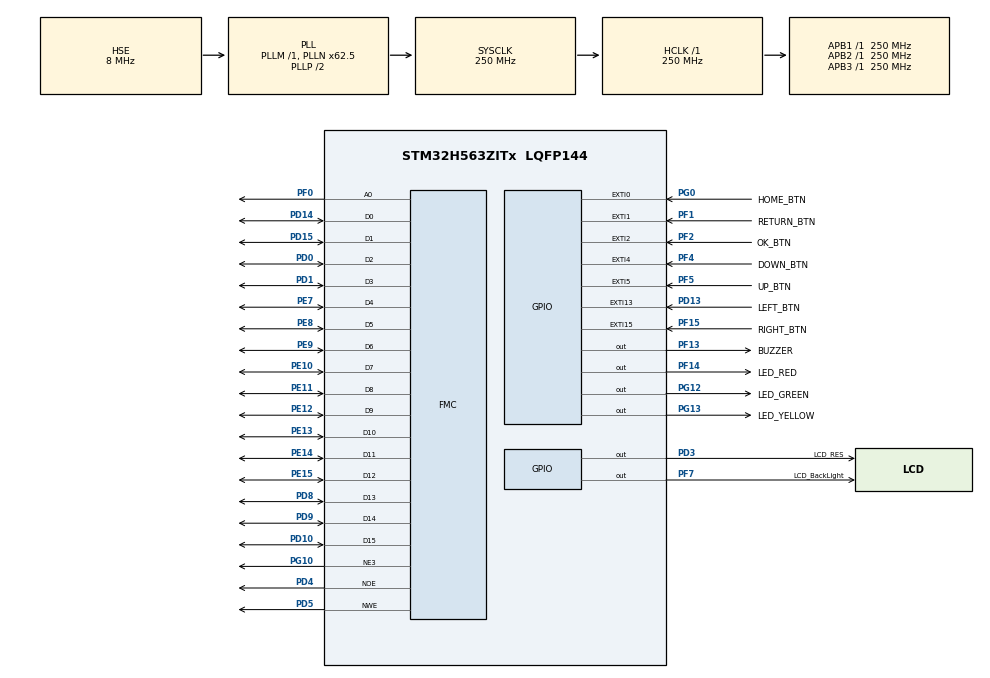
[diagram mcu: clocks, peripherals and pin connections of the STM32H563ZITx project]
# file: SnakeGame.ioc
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BOOTPATH.BootPathName=LEGACY
BOOTPATH.UserSelectedBootPath=LEGACY
CORTEX_M33_NS.Number-Cortex_Memory_Protection_Unit_Region0_OTP_RO_AREAS_Settings=MPU_REGION_NUMBER0
CORTEX_M33_NS.default_mode_Activation=1
CORTEX_M33_NS.userName=CORTEX_M33
FMC.AddressSetupTime1=3
FMC.BusTurnAroundDuration1=0
FMC.DataHoldTime1=3
FMC.DataSetupTime1=4
FMC.ExtendedMode1=FMC_EXTENDED_MODE_DISABLE
Mcu.Family=STM32H5
Mcu.Name=STM32H563ZITx
Mcu.Package=LQFP144
NVIC.EXTI0_IRQn=true\:0\:0\:false\:false\:true\:true\:true\:true
NVIC.EXTI13_IRQn=true\:0\:0\:false\:false\:true\:true\:true\:true
NVIC.EXTI15_IRQn=true\:0\:0\:false\:false\:true\:true\:true\:true
NVIC.EXTI1_IRQn=true\:0\:0\:false\:false\:true\:true\:true\:true
NVIC.EXTI2_IRQn=true\:0\:0\:false\:false\:true\:true\:true\:true
NVIC.EXTI4_IRQn=true\:0\:0\:false\:false\:true\:true\:true\:true
NVIC.EXTI5_IRQn=true\:0\:0\:false\:false\:true\:true\:true\:true
NVIC.PriorityGroup=NVIC_PRIORITYGROUP_4
NVIC.TIM6_IRQn=true\:0\:0\:false\:false\:true\:true\:true\:true
NVIC.TIM7_IRQn=true\:0\:0\:false\:false\:true\:true\:true\:true
PA13(JTMS/SWDIO).Mode=Serial_Wire
PA13(JTMS/SWDIO).Signal=DEBUG_JTMS-SWDIO
PA14(JTCK/SWCLK).Mode=Serial_Wire
PA14(JTCK/SWCLK).Signal=DEBUG_JTCK-SWCLK
PD0.Signal=FMC_D2_DA2
PD1.Signal=FMC_D3_DA3
PD10.Signal=FMC_D15_DA15
PD13.GPIO_Label=LEFT_BTN
PD13.GPIO_ModeDefaultEXTI=GPIO_MODE_IT_FALLING
PD13.GPIO_PuPd=GPIO_PULLUP
PD13.Signal=GPXTI13
PD14.Signal=FMC_D0_DA0
PD15.Signal=FMC_D1_DA1
PD3.GPIO_Label=LCD_RES
PD3.Signal=GPIO_Output
PD4.Signal=FMC_NOE
PD5.Signal=FMC_NWE
PD8.Signal=FMC_D13_DA13
PD9.Signal=FMC_D14_DA14
PE10.Signal=FMC_D7_DA7
PE11.Signal=FMC_D8_DA8
PE12.Signal=FMC_D9_DA9
PE13.Signal=FMC_D10_DA10
PE14.Signal=FMC_D11_DA11
PE15.Signal=FMC_D12_DA12
PE7.Signal=FMC_D4_DA4
PE8.Signal=FMC_D5_DA5
PE9.Signal=FMC_D6_DA6
PF0.Signal=FMC_A0
PF1.GPIO_Label=RETURN_BTN
PF1.GPIO_ModeDefaultEXTI=GPIO_MODE_IT_FALLING
PF1.GPIO_PuPd=GPIO_PULLUP
PF1.Signal=GPXTI1
PF13.GPIO_Label=BUZZER
PF13.GPIO_PuPd=GPIO_NOPULL
PF13.Signal=GPIO_Output
PF14.GPIO_Label=LED_RED
PF14.Signal=GPIO_Output
PF15.GPIO_Label=RIGHT_BTN
PF15.GPIO_ModeDefaultEXTI=GPIO_MODE_IT_FALLING
PF15.GPIO_PuPd=GPIO_PULLUP
PF15.Signal=GPXTI15
PF2.GPIO_Label=OK_BTN
PF2.GPIO_ModeDefaultEXTI=GPIO_MODE_IT_FALLING
PF2.GPIO_PuPd=GPIO_PULLUP
PF2.Signal=GPXTI2
PF4.GPIO_Label=DOWN_BTN
PF4.Signal=GPXTI4
PF5.GPIO_Label=UP_BTN
PF5.GPIO_ModeDefaultEXTI=GPIO_MODE_IT_FALLING
PF5.GPIO_PuPd=GPIO_PULLUP
PF5.Signal=GPXTI5
PF7.GPIO_Label=LCD_BackLight
PF7.Signal=GPIO_Output
PG0.GPIO_Label=HOME_BTN
PG0.GPIO_ModeDefaultEXTI=GPIO_MODE_IT_FALLING
PG0.GPIO_PuPd=GPIO_PULLUP
PG0.Signal=GPXTI0
PG10.Mode=NorPsramChipSelect3_1
PG10.Signal=FMC_NE3
PG12.GPIO_Label=LED_GREEN
PG12.Signal=GPIO_Output
PG13.GPIO_Label=LED_YELLOW
PG13.Signal=GPIO_Output
PH0-OSC_IN(PH0).Mode=HSE-External-Oscillator
PH0-OSC_IN(PH0).Signal=RCC_OSC_IN
PH1-OSC_OUT(PH1).Mode=HSE-External-Oscillator
PH1-OSC_OUT(PH1).Signal=RCC_OSC_OUT
ProjectManager.HeapSize=0x200
ProjectManager.StackSize=0x400
ProjectManager.TargetToolchain=EWARM V9.20
RCC.ADCFreq_Value=250000000
RCC.AHBFreq_Value=250000000
RCC.APB1Freq_Value=250000000
RCC.APB1TimFreq_Value=250000000
RCC.APB2Freq_Value=250000000
RCC.APB2TimFreq_Value=250000000
RCC.APB3Freq_Value=250000000
RCC.CSI_VALUE=4000000
RCC.CortexFreq_Value=250000000
RCC.EPOD_VALUE=8000000
RCC.HCLKFreq_Value=250000000
RCC.HSE_VALUE=8000000
RCC.HSI48_VALUE=48000000
RCC.HSI_VALUE=64000000
RCC.LSE_VALUE=32768
RCC.LSIRC_VALUE=32000
RCC.PLL2FRACN=0
RCC.PLL3FRACN=0
RCC.PLLFRACN=4096
RCC.PLLN=62
RCC.PLLSourceVirtual=RCC_PLL1_SOURCE_HSE
RCC.SYSCLKFreq_VALUE=250000000
RCC.SYSCLKSource=RCC_SYSCLKSOURCE_PLLCLK
RCC.USBFreq_Value=48000000
RCC.VCOOutputFreq_Value=500000000
SH.FMC_A0.0=FMC_A0,A0_1
SH.FMC_D0_DA0.0=FMC_D0,16b-d1
SH.FMC_D10_DA10.0=FMC_D10,16b-d1
SH.FMC_D11_DA11.0=FMC_D11,16b-d1
SH.FMC_D12_DA12.0=FMC_D12,16b-d1
SH.FMC_D13_DA13.0=FMC_D13,16b-d1
SH.FMC_D14_DA14.0=FMC_D14,16b-d1
SH.FMC_D15_DA15.0=FMC_D15,16b-d1
SH.FMC_D1_DA1.0=FMC_D1,16b-d1
SH.FMC_D2_DA2.0=FMC_D2,16b-d1
SH.FMC_D3_DA3.0=FMC_D3,16b-d1
SH.FMC_D4_DA4.0=FMC_D4,16b-d1
SH.FMC_D5_DA5.0=FMC_D5,16b-d1
SH.FMC_D6_DA6.0=FMC_D6,16b-d1
SH.FMC_D7_DA7.0=FMC_D7,16b-d1
SH.FMC_D8_DA8.0=FMC_D8,16b-d1
SH.FMC_D9_DA9.0=FMC_D9,16b-d1
SH.FMC_NOE.0=FMC_NOE,Lcd1
SH.FMC_NWE.0=FMC_NWE,Lcd1
TIM6.PeriodNoDither=99
TIM6.Prescaler=249
TIM7.PeriodNoDither=99
TIM7.Prescaler=249
VP_BOOTPATH_VS_BOOTPATH.Mode=BP_Activate
VP_CORTEX_M33_NS_VS_Hclk.Mode=Hclk_Mode
VP_ICACHE_VS_ICACHE.Mode=DirectMappedCache
VP_MEMORYMAP_VS_MEMORYMAP.Mode=CurAppReg
VP_PWR_VS_LPOM.Mode=PowerOptimisation
VP_PWR_VS_SECSignals.Mode=Security/Privilege
VP_TIM6_VS_ClockSourceINT.Mode=Enable_Timer
VP_TIM7_VS_ClockSourceINT.Mode=Enable_Timer
board=custom

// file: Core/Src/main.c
/* USER CODE BEGIN Header */
/**
  ******************************************************************************
  * @file           : main.c
  * @brief          : Main program body
  ******************************************************************************
  * @attention
  *
  * Copyright (c) 2026 STMicroelectronics.
  * All rights reserved.
  *
  * This software is licensed under terms that can be found in the LICENSE file
  * in the root directory of this software component.
  * If no LICENSE file comes with this software, it is provided AS-IS.
  *
  ******************************************************************************
  */
/* USER CODE END Header */
#include "main.h"

TIM_HandleTypeDef htim6;
TIM_HandleTypeDef htim7;

SRAM_HandleTypeDef hsram1;

void SystemClock_Config(void);
static void MPU_Config(void);
static void MX_GPIO_Init(void);
static void MX_ICACHE_Init(void);
static void MX_TIM6_Init(void);
static void MX_TIM7_Init(void);
static void MX_FMC_Init(void);

int main(void)
{

  /* MCU Configuration--------------------------------------------------------*/

  /* MPU Configuration--------------------------------------------------------*/
  MPU_Config();

  /* Reset of all peripherals, Initializes the Flash interface and the Systick. */
  HAL_Init();

  /* Configure the system clock */
  SystemClock_Config();

  /* Initialize all configured peripherals */
  MX_GPIO_Init();
  MX_ICACHE_Init();
  MX_TIM6_Init();
  MX_TIM7_Init();
  MX_FMC_Init();
  /* USER CODE BEGIN 2 */
  LedDriver_Init();
  /* USER CODE END 2 */

  /* Infinite loop */
  while (1)
  {

  }
}

void SystemClock_Config(void)
{
  RCC_OscInitTypeDef RCC_OscInitStruct = {0};
  RCC_ClkInitTypeDef RCC_ClkInitStruct = {0};

  /** Configure the main internal regulator output voltage
  */
  __HAL_PWR_VOLTAGESCALING_CONFIG(PWR_REGULATOR_VOLTAGE_SCALE0);

  while(!__HAL_PWR_GET_FLAG(PWR_FLAG_VOSRDY)) {}

  /** Initializes the RCC Oscillators according to the specified parameters
  * in the RCC_OscInitTypeDef structure.
  */
  RCC_OscInitStruct.OscillatorType = RCC_OSCILLATORTYPE_HSE;
  RCC_OscInitStruct.HSEState = RCC_HSE_ON;
  RCC_OscInitStruct.PLL.PLLState = RCC_PLL_ON;
  RCC_OscInitStruct.PLL.PLLSource = RCC_PLL1_SOURCE_HSE;
  RCC_OscInitStruct.PLL.PLLM = 1;
  RCC_OscInitStruct.PLL.PLLN = 62;
  RCC_OscInitStruct.PLL.PLLP = 2;
  RCC_OscInitStruct.PLL.PLLQ = 2;
  RCC_OscInitStruct.PLL.PLLR = 2;
  RCC_OscInitStruct.PLL.PLLRGE = RCC_PLL1_VCIRANGE_3;
  RCC_OscInitStruct.PLL.PLLVCOSEL = RCC_PLL1_VCORANGE_WIDE;
  RCC_OscInitStruct.PLL.PLLFRACN = 4096;
  if (HAL_RCC_OscConfig(&RCC_OscInitStruct) != HAL_OK)
  {
    Error_Handler();
  }

  /** Initializes the CPU, AHB and APB buses clocks
  */
  RCC_ClkInitStruct.ClockType = RCC_CLOCKTYPE_HCLK|RCC_CLOCKTYPE_SYSCLK
                              |RCC_CLOCKTYPE_PCLK1|RCC_CLOCKTYPE_PCLK2
                              |RCC_CLOCKTYPE_PCLK3;
  RCC_ClkInitStruct.SYSCLKSource = RCC_SYSCLKSOURCE_PLLCLK;
  RCC_ClkInitStruct.AHBCLKDivider = RCC_SYSCLK_DIV1;
  RCC_ClkInitStruct.APB1CLKDivider = RCC_HCLK_DIV1;
  RCC_ClkInitStruct.APB2CLKDivider = RCC_HCLK_DIV1;
  RCC_ClkInitStruct.APB3CLKDivider = RCC_HCLK_DIV1;

  if (HAL_RCC_ClockConfig(&RCC_ClkInitStruct, FLASH_LATENCY_5) != HAL_OK)
  {
    Error_Handler();
  }

  /** Configure the programming delay
  */
  __HAL_FLASH_SET_PROGRAM_DELAY(FLASH_PROGRAMMING_DELAY_2);
}

static void MX_ICACHE_Init(void)
{

  /** Enable instruction cache in 1-way (direct mapped cache)
  */
  if (HAL_ICACHE_ConfigAssociativityMode(ICACHE_1WAY) != HAL_OK)
  {
    Error_Handler();
  }
  if (HAL_ICACHE_Enable() != HAL_OK)
  {
    Error_Handler();
  }

}

static void MX_TIM6_Init(void)
{

  TIM_MasterConfigTypeDef sMasterConfig = {0};

  htim6.Instance = TIM6;
  htim6.Init.Prescaler = 249;
  htim6.Init.CounterMode = TIM_COUNTERMODE_UP;
  htim6.Init.Period = 99;
  htim6.Init.AutoReloadPreload = TIM_AUTORELOAD_PRELOAD_DISABLE;
  if (HAL_TIM_Base_Init(&htim6) != HAL_OK)
  {
    Error_Handler();
  }
  sMasterConfig.MasterOutputTrigger = TIM_TRGO_RESET;
  sMasterConfig.MasterSlaveMode = TIM_MASTERSLAVEMODE_DISABLE;
  if (HAL_TIMEx_MasterConfigSynchronization(&htim6, &sMasterConfig) != HAL_OK)
  {
    Error_Handler();
  }

}

static void MX_TIM7_Init(void)
{

  TIM_MasterConfigTypeDef sMasterConfig = {0};

  htim7.Instance = TIM7;
  htim7.Init.Prescaler = 249;
  htim7.Init.CounterMode = TIM_COUNTERMODE_UP;
  htim7.Init.Period = 99;
  htim7.Init.AutoReloadPreload = TIM_AUTORELOAD_PRELOAD_DISABLE;
  if (HAL_TIM_Base_Init(&htim7) != HAL_OK)
  {
    Error_Handler();
  }
  sMasterConfig.MasterOutputTrigger = TIM_TRGO_RESET;
  sMasterConfig.MasterSlaveMode = TIM_MASTERSLAVEMODE_DISABLE;
  if (HAL_TIMEx_MasterConfigSynchronization(&htim7, &sMasterConfig) != HAL_OK)
  {
    Error_Handler();
  }

}

/* FMC initialization function */
static void MX_FMC_Init(void)
{

  FMC_NORSRAM_TimingTypeDef Timing = {0};

  /** Perform the SRAM1 memory initialization sequence
  */
  hsram1.Instance = FMC_NORSRAM_DEVICE;
  hsram1.Extended = FMC_NORSRAM_EXTENDED_DEVICE;
  /* hsram1.Init */
  hsram1.Init.NSBank = FMC_NORSRAM_BANK3;
  hsram1.Init.DataAddressMux = FMC_DATA_ADDRESS_MUX_DISABLE;
  hsram1.Init.MemoryType = FMC_MEMORY_TYPE_SRAM;
  hsram1.Init.MemoryDataWidth = FMC_NORSRAM_MEM_BUS_WIDTH_16;
  hsram1.Init.BurstAccessMode = FMC_BURST_ACCESS_MODE_DISABLE;
  hsram1.Init.WaitSignalPolarity = FMC_WAIT_SIGNAL_POLARITY_LOW;
  hsram1.Init.WaitSignalActive = FMC_WAIT_TIMING_BEFORE_WS;
  hsram1.Init.WriteOperation = FMC_WRITE_OPERATION_ENABLE;
  hsram1.Init.WaitSignal = FMC_WAIT_SIGNAL_DISABLE;
  hsram1.Init.ExtendedMode = FMC_EXTENDED_MODE_DISABLE;
  hsram1.Init.AsynchronousWait = FMC_ASYNCHRONOUS_WAIT_DISABLE;
  hsram1.Init.WriteBurst = FMC_WRITE_BURST_DISABLE;
  hsram1.Init.ContinuousClock = FMC_CONTINUOUS_CLOCK_SYNC_ONLY;
  hsram1.Init.WriteFifo = FMC_WRITE_FIFO_ENABLE;
  hsram1.Init.NBLSetupTime = 0;
  hsram1.Init.PageSize = FMC_PAGE_SIZE_NONE;
  hsram1.Init.MaxChipSelectPulse = DISABLE;
  /* Timing */
  Timing.AddressSetupTime = 3;
  Timing.AddressHoldTime = 15;
  Timing.DataSetupTime = 4;
  Timing.DataHoldTime = 3;
  Timing.BusTurnAroundDuration = 0;
  Timing.CLKDivision = 16;
  Timing.DataLatency = 17;
  Timing.AccessMode = FMC_ACCESS_MODE_A;
  /* ExtTiming */

  if (HAL_SRAM_Init(&hsram1, &Timing, NULL) != HAL_OK)
  {
    Error_Handler( );
  }

}

static void MX_GPIO_Init(void)
{
  GPIO_InitTypeDef GPIO_InitStruct = {0};

  /* GPIO Ports Clock Enable */
  __HAL_RCC_GPIOF_CLK_ENABLE();
  __HAL_RCC_GPIOH_CLK_ENABLE();
  __HAL_RCC_GPIOG_CLK_ENABLE();
  __HAL_RCC_GPIOE_CLK_ENABLE();
  __HAL_RCC_GPIOD_CLK_ENABLE();
  __HAL_RCC_GPIOA_CLK_ENABLE();

  /*Configure GPIO pin Output Level */
  HAL_GPIO_WritePin(GPIOF, LCD_BackLight_Pin|BUZZER_Pin|LED_RED_Pin, GPIO_PIN_RESET);

  /*Configure GPIO pin Output Level */
  HAL_GPIO_WritePin(LCD_RES_GPIO_Port, LCD_RES_Pin, GPIO_PIN_RESET);

  /*Configure GPIO pin Output Level */
  HAL_GPIO_WritePin(GPIOG, LED_GREEN_Pin|LED_YELLOW_Pin, GPIO_PIN_RESET);

  /*Configure GPIO pins : RETURN_BTN_Pin OK_BTN_Pin UP_BTN_Pin RIGHT_BTN_Pin */
  GPIO_InitStruct.Pin = RETURN_BTN_Pin|OK_BTN_Pin|UP_BTN_Pin|RIGHT_BTN_Pin;
  GPIO_InitStruct.Mode = GPIO_MODE_IT_FALLING;
  GPIO_InitStruct.Pull = GPIO_PULLUP;
  HAL_GPIO_Init(GPIOF, &GPIO_InitStruct);

  /*Configure GPIO pin : DOWN_BTN_Pin */
  GPIO_InitStruct.Pin = DOWN_BTN_Pin;
  GPIO_InitStruct.Mode = GPIO_MODE_IT_RISING;
  GPIO_InitStruct.Pull = GPIO_NOPULL;
  HAL_GPIO_Init(DOWN_BTN_GPIO_Port, &GPIO_InitStruct);

  /*Configure GPIO pins : LCD_BackLight_Pin BUZZER_Pin LED_RED_Pin */
  GPIO_InitStruct.Pin = LCD_BackLight_Pin|BUZZER_Pin|LED_RED_Pin;
  GPIO_InitStruct.Mode = GPIO_MODE_OUTPUT_PP;
  GPIO_InitStruct.Pull = GPIO_NOPULL;
  GPIO_InitStruct.Speed = GPIO_SPEED_FREQ_LOW;
  HAL_GPIO_Init(GPIOF, &GPIO_InitStruct);

  /*Configure GPIO pin : HOME_BTN_Pin */
  GPIO_InitStruct.Pin = HOME_BTN_Pin;
  GPIO_InitStruct.Mode = GPIO_MODE_IT_FALLING;
  GPIO_InitStruct.Pull = GPIO_PULLUP;
  HAL_GPIO_Init(HOME_BTN_GPIO_Port, &GPIO_InitStruct);

  /*Configure GPIO pin : LEFT_BTN_Pin */
  GPIO_InitStruct.Pin = LEFT_BTN_Pin;
  GPIO_InitStruct.Mode = GPIO_MODE_IT_FALLING;
  GPIO_InitStruct.Pull = GPIO_PULLUP;
  HAL_GPIO_Init(LEFT_BTN_GPIO_Port, &GPIO_InitStruct);

  /*Configure GPIO pin : PA13 */
  GPIO_InitStruct.Pin = GPIO_PIN_13;
  GPIO_InitStruct.Mode = GPIO_MODE_AF_PP;
  GPIO_InitStruct.Pull = GPIO_PULLUP;
  GPIO_InitStruct.Speed = GPIO_SPEED_FREQ_LOW;
  GPIO_InitStruct.Alternate = GPIO_AF0_TRACE;
  HAL_GPIO_Init(GPIOA, &GPIO_InitStruct);

  /*Configure GPIO pin : LCD_RES_Pin */
  GPIO_InitStruct.Pin = LCD_RES_Pin;
  GPIO_InitStruct.Mode = GPIO_MODE_OUTPUT_PP;
  GPIO_InitStruct.Pull = GPIO_NOPULL;
  GPIO_InitStruct.Speed = GPIO_SPEED_FREQ_LOW;
  HAL_GPIO_Init(LCD_RES_GPIO_Port, &GPIO_InitStruct);

  /*Configure GPIO pins : LED_GREEN_Pin LED_YELLOW_Pin */
  GPIO_InitStruct.Pin = LED_GREEN_Pin|LED_YELLOW_Pin;
  GPIO_InitStruct.Mode = GPIO_MODE_OUTPUT_PP;
  GPIO_InitStruct.Pull = GPIO_NOPULL;
  GPIO_InitStruct.Speed = GPIO_SPEED_FREQ_LOW;
  HAL_GPIO_Init(GPIOG, &GPIO_InitStruct);

  /* EXTI interrupt init*/
  HAL_NVIC_SetPriority(EXTI0_IRQn, 0, 0);
  HAL_NVIC_EnableIRQ(EXTI0_IRQn);

  HAL_NVIC_SetPriority(EXTI1_IRQn, 0, 0);
  HAL_NVIC_EnableIRQ(EXTI1_IRQn);

  HAL_NVIC_SetPriority(EXTI2_IRQn, 0, 0);
  HAL_NVIC_EnableIRQ(EXTI2_IRQn);

  HAL_NVIC_SetPriority(EXTI4_IRQn, 0, 0);
  HAL_NVIC_EnableIRQ(EXTI4_IRQn);

  HAL_NVIC_SetPriority(EXTI5_IRQn, 0, 0);
  HAL_NVIC_EnableIRQ(EXTI5_IRQn);

  HAL_NVIC_SetPriority(EXTI13_IRQn, 0, 0);
  HAL_NVIC_EnableIRQ(EXTI13_IRQn);

  HAL_NVIC_SetPriority(EXTI15_IRQn, 0, 0);
  HAL_NVIC_EnableIRQ(EXTI15_IRQn);

}

 /* MPU Configuration */

void MPU_Config(void)
{
  MPU_Region_InitTypeDef MPU_InitStruct = {0};
  MPU_Attributes_InitTypeDef MPU_AttributesInit = {0};

  /* Disables the MPU */
  HAL_MPU_Disable();

  /** Initializes and configures the Region 0 and the memory to be protected
  */
  MPU_InitStruct.Enable = MPU_REGION_ENABLE;
  MPU_InitStruct.Number = MPU_REGION_NUMBER0;
  MPU_InitStruct.BaseAddress = 0x08FFF000;
  MPU_InitStruct.LimitAddress = 0x08FFFFFF;
  MPU_InitStruct.AttributesIndex = MPU_ATTRIBUTES_NUMBER0;
  MPU_InitStruct.AccessPermission = MPU_REGION_ALL_RO;
  MPU_InitStruct.DisableExec = MPU_INSTRUCTION_ACCESS_DISABLE;
  MPU_InitStruct.IsShareable = MPU_ACCESS_NOT_SHAREABLE;

  HAL_MPU_ConfigRegion(&MPU_InitStruct);

  /** Initializes and configures the Attribute 0 and the memory to be protected
  */
  MPU_AttributesInit.Number = MPU_ATTRIBUTES_NUMBER0;
  MPU_AttributesInit.Attributes = INNER_OUTER(MPU_NOT_CACHEABLE);

  HAL_MPU_ConfigMemoryAttributes(&MPU_AttributesInit);
  /* Enables the MPU */
  HAL_MPU_Enable(MPU_PRIVILEGED_DEFAULT);

}

void Error_Handler(void)
{
  __disable_irq();
  while (1)
  {
  }
}
